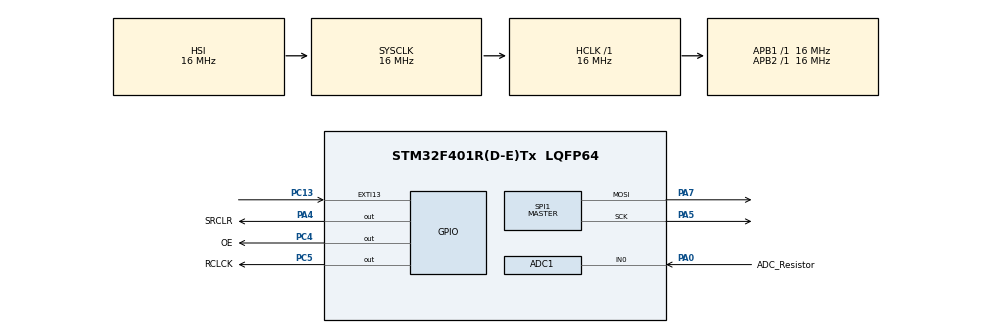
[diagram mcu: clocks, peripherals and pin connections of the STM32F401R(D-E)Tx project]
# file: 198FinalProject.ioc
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ADC1.Channel-1\#ChannelRegularConversion=ADC_CHANNEL_0
ADC1.EOCSelection=ADC_EOC_SINGLE_CONV
ADC1.NbrOfConversionFlag=1
ADC1.Rank-1\#ChannelRegularConversion=1
ADC1.SamplingTime-1\#ChannelRegularConversion=ADC_SAMPLETIME_3CYCLES
ADC1.master=1
Mcu.Family=STM32F4
Mcu.Name=STM32F401R(D-E)Tx
Mcu.Package=LQFP64
NVIC.EXTI15_10_IRQn=true\:0\:0\:false\:false\:true\:true\:true\:true
NVIC.PriorityGroup=NVIC_PRIORITYGROUP_4
PA0-WKUP.GPIO_Label=ADC_Resistor
PA0-WKUP.Signal=ADCx_IN0
PA4.GPIO_Label=SRCLR
PA4.Signal=GPIO_Output
PA5.Mode=TX_Only_Simplex_Unidirect_Master
PA5.Signal=SPI1_SCK
PA7.Mode=TX_Only_Simplex_Unidirect_Master
PA7.Signal=SPI1_MOSI
PC13-ANTI_TAMP.GPIO_ModeDefaultEXTI=GPIO_MODE_IT_FALLING
PC13-ANTI_TAMP.Signal=GPXTI13
PC4.GPIO_Label=OE
PC4.Signal=GPIO_Output
PC5.GPIO_Label=RCLCK
PC5.Signal=GPIO_Output
ProjectManager.HeapSize=0x200
ProjectManager.StackSize=0x400
ProjectManager.TargetToolchain=STM32CubeIDE
RCC.AHBFreq_Value=16000000
RCC.APB1Freq_Value=16000000
RCC.APB2Freq_Value=16000000
RCC.CortexFreq_Value=16000000
RCC.HSE_VALUE=25000000
RCC.HSI_VALUE=16000000
RCC.LSE_VALUE=32768
RCC.SYSCLKFreq_VALUE=16000000
RCC.VCOOutputFreq_Value=192000000
SH.ADCx_IN0.0=ADC1_IN0,IN0
SPI1.BaudRatePrescaler=SPI_BAUDRATEPRESCALER_16
SPI1.Direction=SPI_DIRECTION_2LINES
SPI1.FirstBit=SPI_FIRSTBIT_LSB
SPI1.Mode=SPI_MODE_MASTER
SPI1.VirtualType=VM_MASTER
board=custom

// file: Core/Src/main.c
/* USER CODE BEGIN Header */
/**
  ******************************************************************************
  * @file           : main.c
  * @brief          : Main program body
  ******************************************************************************
  * @attention
  *
  * Copyright (c) 2022 STMicroelectronics.
  * All rights reserved.
  *
  * This software is licensed under terms that can be found in the LICENSE file
  * in the root directory of this software component.
  * If no LICENSE file comes with this software, it is provided AS-IS.
  *
  ******************************************************************************
  */
/* USER CODE END Header */
#include "main.h"
#include <stdint.h>
#include "ADCToWeightModule/ADCToWeightModule.h"
#include "FlashMemoryAPI/flash_memory_api.h"
#include "FlashMemoryAPI/FlashWeightSenseTypeDef.h"
#include "TestSuite/Test_Suite.h"

 ADC_HandleTypeDef hadc1;

SPI_HandleTypeDef hspi1;

void SystemClock_Config(void);
static void MX_GPIO_Init(void);
static void MX_SPI1_Init(void);
static void MX_ADC1_Init(void);

int main(void)
{

  /* MCU Configuration--------------------------------------------------------*/

  /* Reset of all peripherals, Initializes the Flash interface and the Systick. */
  HAL_Init();

  /* Configure the system clock */
  SystemClock_Config();

  /* Initialize all configured peripherals */
  MX_GPIO_Init();
  MX_SPI1_Init();
  MX_ADC1_Init();

  /* Infinite loop */

  /* USER CODE BEGIN WHILE */

  while (1)
  {

	uint32_t mass = 0;
	HAL_ADC_Start(&hadc1);
	HAL_ADC_PollForConversion(&hadc1, 1000);
	uint32_t adc_val = HAL_ADC_GetValue(&hadc1);
	mass = ConvertADCValToMass(adc_val);
	DisplayInteger(mass, &hspi1);
	HAL_Delay(100);
	HAL_ADC_Stop(&hadc1);
	  //save_to_flash(&data[0], 2);
    /* USER CODE END WHILE */

  }
}

void SystemClock_Config(void)
{
  RCC_OscInitTypeDef RCC_OscInitStruct = {0};
  RCC_ClkInitTypeDef RCC_ClkInitStruct = {0};

  /** Configure the main internal regulator output voltage
  */
  __HAL_RCC_PWR_CLK_ENABLE();
  __HAL_PWR_VOLTAGESCALING_CONFIG(PWR_REGULATOR_VOLTAGE_SCALE2);

  /** Initializes the RCC Oscillators according to the specified parameters
  * in the RCC_OscInitTypeDef structure.
  */
  RCC_OscInitStruct.OscillatorType = RCC_OSCILLATORTYPE_HSI;
  RCC_OscInitStruct.HSIState = RCC_HSI_ON;
  RCC_OscInitStruct.HSICalibrationValue = RCC_HSICALIBRATION_DEFAULT;
  RCC_OscInitStruct.PLL.PLLState = RCC_PLL_NONE;
  if (HAL_RCC_OscConfig(&RCC_OscInitStruct) != HAL_OK)
  {
    Error_Handler();
  }

  /** Initializes the CPU, AHB and APB buses clocks
  */
  RCC_ClkInitStruct.ClockType = RCC_CLOCKTYPE_HCLK|RCC_CLOCKTYPE_SYSCLK
                              |RCC_CLOCKTYPE_PCLK1|RCC_CLOCKTYPE_PCLK2;
  RCC_ClkInitStruct.SYSCLKSource = RCC_SYSCLKSOURCE_HSI;
  RCC_ClkInitStruct.AHBCLKDivider = RCC_SYSCLK_DIV1;
  RCC_ClkInitStruct.APB1CLKDivider = RCC_HCLK_DIV1;
  RCC_ClkInitStruct.APB2CLKDivider = RCC_HCLK_DIV1;

  if (HAL_RCC_ClockConfig(&RCC_ClkInitStruct, FLASH_LATENCY_0) != HAL_OK)
  {
    Error_Handler();
  }
}

static void MX_ADC1_Init(void)
{

  ADC_ChannelConfTypeDef sConfig = {0};

  /** Configure the global features of the ADC (Clock, Resolution, Data Alignment and number of conversion)
  */
  hadc1.Instance = ADC1;
  hadc1.Init.ClockPrescaler = ADC_CLOCK_SYNC_PCLK_DIV2;
  hadc1.Init.Resolution = ADC_RESOLUTION_12B;
  hadc1.Init.ScanConvMode = DISABLE;
  hadc1.Init.ContinuousConvMode = DISABLE;
  hadc1.Init.DiscontinuousConvMode = DISABLE;
  hadc1.Init.ExternalTrigConvEdge = ADC_EXTERNALTRIGCONVEDGE_NONE;
  hadc1.Init.ExternalTrigConv = ADC_SOFTWARE_START;
  hadc1.Init.DataAlign = ADC_DATAALIGN_RIGHT;
  hadc1.Init.NbrOfConversion = 1;
  hadc1.Init.DMAContinuousRequests = DISABLE;
  hadc1.Init.EOCSelection = ADC_EOC_SINGLE_CONV;
  if (HAL_ADC_Init(&hadc1) != HAL_OK)
  {
    Error_Handler();
  }

  /** Configure for the selected ADC regular channel its corresponding rank in the sequencer and its sample time.
  */
  sConfig.Channel = ADC_CHANNEL_0;
  sConfig.Rank = 1;
  sConfig.SamplingTime = ADC_SAMPLETIME_3CYCLES;
  if (HAL_ADC_ConfigChannel(&hadc1, &sConfig) != HAL_OK)
  {
    Error_Handler();
  }

}

static void MX_SPI1_Init(void)
{

  /* SPI1 parameter configuration*/
  hspi1.Instance = SPI1;
  hspi1.Init.Mode = SPI_MODE_MASTER;
  hspi1.Init.Direction = SPI_DIRECTION_2LINES;
  hspi1.Init.DataSize = SPI_DATASIZE_8BIT;
  hspi1.Init.CLKPolarity = SPI_POLARITY_LOW;
  hspi1.Init.CLKPhase = SPI_PHASE_1EDGE;
  hspi1.Init.NSS = SPI_NSS_SOFT;
  hspi1.Init.BaudRatePrescaler = SPI_BAUDRATEPRESCALER_16;
  hspi1.Init.FirstBit = SPI_FIRSTBIT_LSB;
  hspi1.Init.TIMode = SPI_TIMODE_DISABLE;
  hspi1.Init.CRCCalculation = SPI_CRCCALCULATION_DISABLE;
  hspi1.Init.CRCPolynomial = 10;
  if (HAL_SPI_Init(&hspi1) != HAL_OK)
  {
    Error_Handler();
  }

}

static void MX_GPIO_Init(void)
{
  GPIO_InitTypeDef GPIO_InitStruct = {0};

  /* GPIO Ports Clock Enable */
  __HAL_RCC_GPIOC_CLK_ENABLE();
  __HAL_RCC_GPIOA_CLK_ENABLE();

  /*Configure GPIO pin Output Level */
  HAL_GPIO_WritePin(SRCLR_GPIO_Port, SRCLR_Pin, GPIO_PIN_RESET);

  /*Configure GPIO pin Output Level */
  HAL_GPIO_WritePin(GPIOC, OE_Pin|RCLCK_Pin, GPIO_PIN_RESET);

  /*Configure GPIO pin : PC13 */
  GPIO_InitStruct.Pin = GPIO_PIN_13;
  GPIO_InitStruct.Mode = GPIO_MODE_IT_FALLING;
  GPIO_InitStruct.Pull = GPIO_NOPULL;
  HAL_GPIO_Init(GPIOC, &GPIO_InitStruct);

  /*Configure GPIO pin : SRCLR_Pin */
  GPIO_InitStruct.Pin = SRCLR_Pin;
  GPIO_InitStruct.Mode = GPIO_MODE_OUTPUT_PP;
  GPIO_InitStruct.Pull = GPIO_NOPULL;
  GPIO_InitStruct.Speed = GPIO_SPEED_FREQ_LOW;
  HAL_GPIO_Init(SRCLR_GPIO_Port, &GPIO_InitStruct);

  /*Configure GPIO pins : OE_Pin RCLCK_Pin */
  GPIO_InitStruct.Pin = OE_Pin|RCLCK_Pin;
  GPIO_InitStruct.Mode = GPIO_MODE_OUTPUT_PP;
  GPIO_InitStruct.Pull = GPIO_NOPULL;
  GPIO_InitStruct.Speed = GPIO_SPEED_FREQ_LOW;
  HAL_GPIO_Init(GPIOC, &GPIO_InitStruct);

  /* EXTI interrupt init*/
  HAL_NVIC_SetPriority(EXTI15_10_IRQn, 0, 0);
  HAL_NVIC_EnableIRQ(EXTI15_10_IRQn);

}

void Error_Handler(void)
{
  __disable_irq();
  while (1)
  {
  }
}
